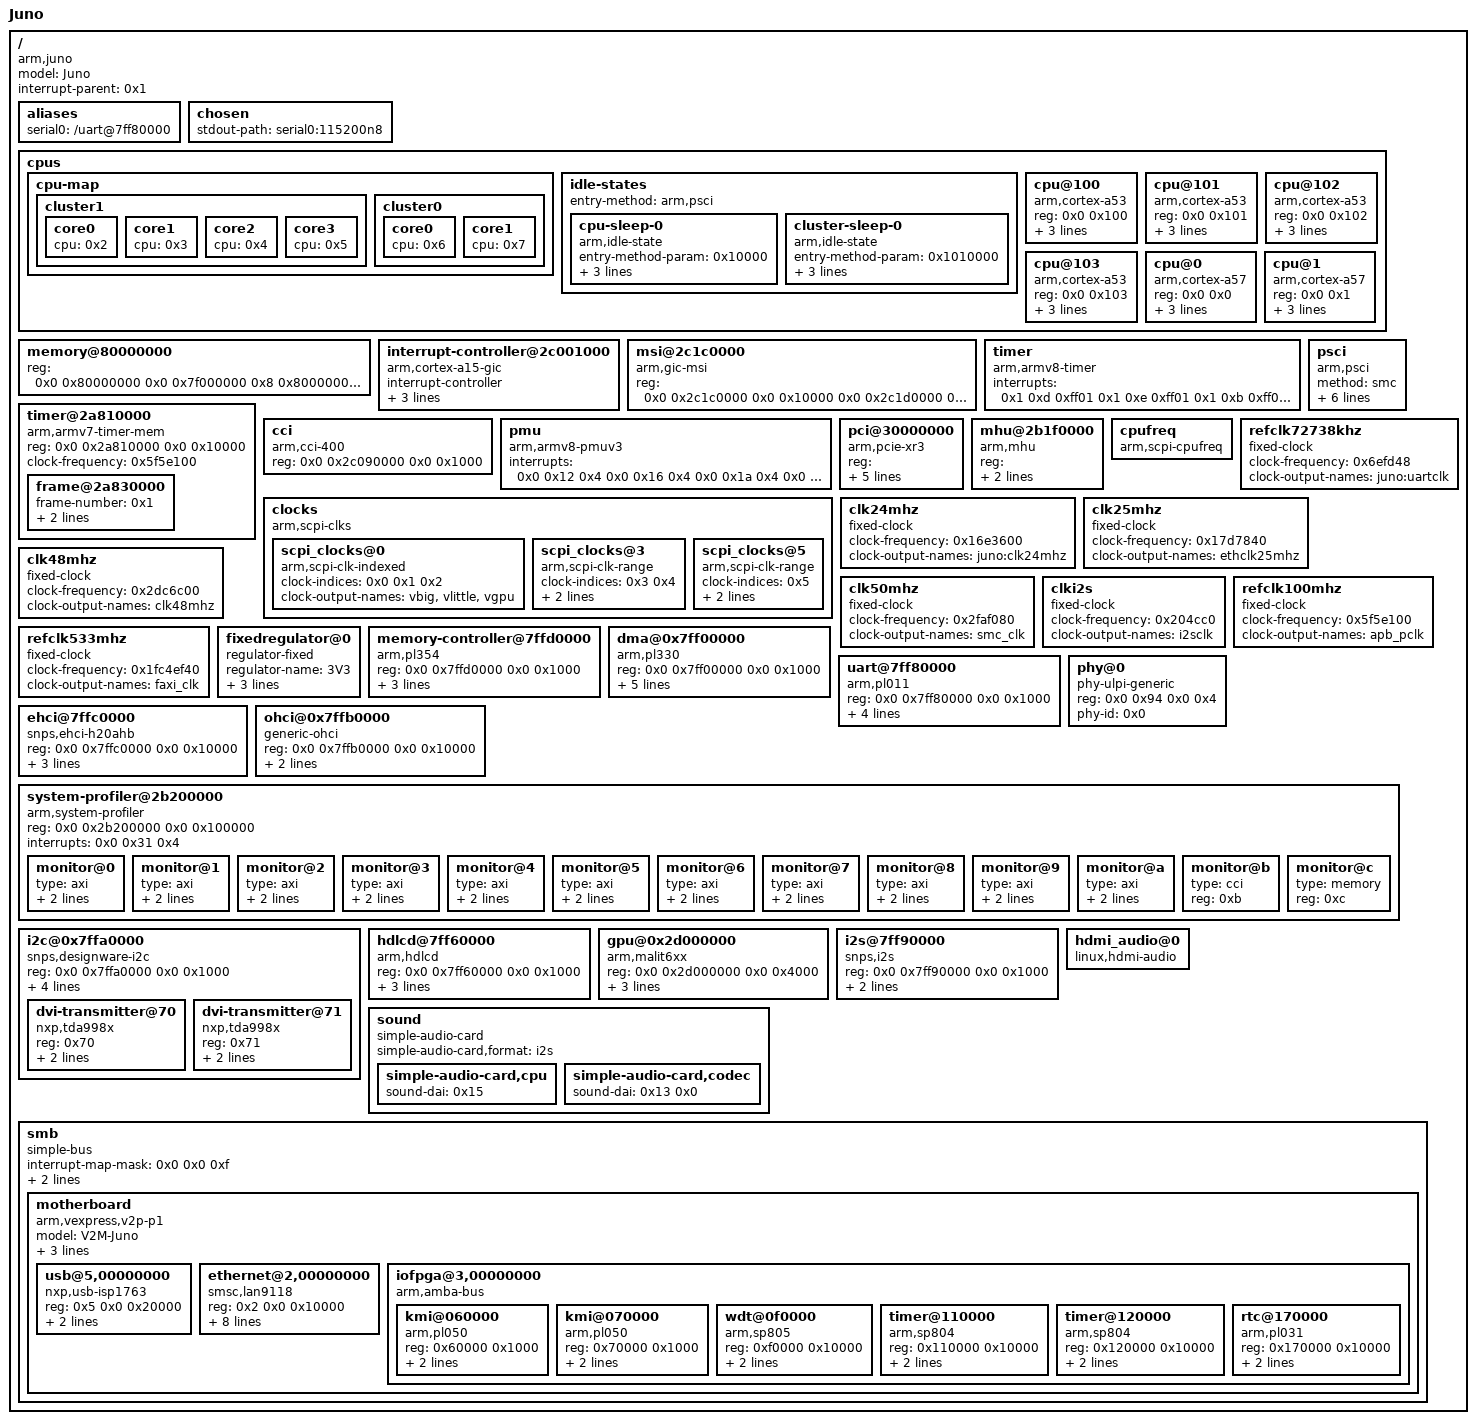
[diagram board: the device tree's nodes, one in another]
/dts-v1/;

/ {
	model = "Juno";
	compatible = "arm,juno", "arm,vexpress";
	interrupt-parent = <0x1>;
	#address-cells = <0x2>;
	#size-cells = <0x2>;

	aliases {
		serial0 = "/uart@7ff80000";
	};

	chosen {
		stdout-path = "serial0:115200n8";
	};

	cpus {
		#address-cells = <0x2>;
		#size-cells = <0x0>;

		cpu-map {

			cluster1 {

				core0 {
					cpu = <0x2>;
				};

				core1 {
					cpu = <0x3>;
				};

				core2 {
					cpu = <0x4>;
				};

				core3 {
					cpu = <0x5>;
				};
			};

			cluster0 {

				core0 {
					cpu = <0x6>;
				};

				core1 {
					cpu = <0x7>;
				};
			};
		};

		idle-states {
			entry-method = "arm,psci";

			cpu-sleep-0 {
				compatible = "arm,idle-state";
				entry-method-param = <0x10000>;
				entry-latency-us = <0x28>;
				exit-latency-us = <0x64>;
				min-residency-us = <0x96>;
				linux,phandle = <0x9>;
				phandle = <0x9>;
			};

			cluster-sleep-0 {
				compatible = "arm,idle-state";
				entry-method-param = <0x1010000>;
				entry-latency-us = <0x1f4>;
				exit-latency-us = <0x3e8>;
				min-residency-us = <0x9c4>;
				linux,phandle = <0xa>;
				phandle = <0xa>;
			};
		};

		cpu@100 {
			device_type = "cpu";
			compatible = "arm,cortex-a53", "arm,armv8";
			reg = <0x0 0x100>;
			enable-method = "psci";
			clocks = <0x8 0x1>;
			clock-names = "vlittle";
			cpu-idle-states = <0x9 0xa>;
			linux,phandle = <0x2>;
			phandle = <0x2>;
		};

		cpu@101 {
			device_type = "cpu";
			compatible = "arm,cortex-a53", "arm,armv8";
			reg = <0x0 0x101>;
			enable-method = "psci";
			clocks = <0x8 0x1>;
			clock-names = "vlittle";
			cpu-idle-states = <0x9 0xa>;
			linux,phandle = <0x3>;
			phandle = <0x3>;
		};

		cpu@102 {
			device_type = "cpu";
			compatible = "arm,cortex-a53", "arm,armv8";
			reg = <0x0 0x102>;
			enable-method = "psci";
			clocks = <0x8 0x1>;
			clock-names = "vlittle";
			cpu-idle-states = <0x9 0xa>;
			linux,phandle = <0x4>;
			phandle = <0x4>;
		};

		cpu@103 {
			device_type = "cpu";
			compatible = "arm,cortex-a53", "arm,armv8";
			reg = <0x0 0x103>;
			enable-method = "psci";
			clocks = <0x8 0x1>;
			clock-names = "vlittle";
			cpu-idle-states = <0x9 0xa>;
			linux,phandle = <0x5>;
			phandle = <0x5>;
		};

		cpu@0 {
			device_type = "cpu";
			compatible = "arm,cortex-a57", "arm,armv8";
			reg = <0x0 0x0>;
			enable-method = "psci";
			clocks = <0x8 0x0>;
			clock-names = "vbig";
			cpu-idle-states = <0x9 0xa>;
			linux,phandle = <0x6>;
			phandle = <0x6>;
		};

		cpu@1 {
			device_type = "cpu";
			compatible = "arm,cortex-a57", "arm,armv8";
			reg = <0x0 0x1>;
			enable-method = "psci";
			clocks = <0x8 0x0>;
			clock-names = "vbig";
			cpu-idle-states = <0x9 0xa>;
			linux,phandle = <0x7>;
			phandle = <0x7>;
		};
	};

	memory@80000000 {
		device_type = "memory";
		reg = <0x0 0x80000000 0x0 0x7f000000 0x8 0x80000000 0x1 0x80000000>;
	};

	interrupt-controller@2c001000 {
		compatible = "arm,cortex-a15-gic", "arm,cortex-a9-gic";
		#interrupt-cells = <0x3>;
		#address-cells = <0x0>;
		interrupt-controller;
		reg = <0x0 0x2c010000 0x0 0x1000 0x0 0x2c02f000 0x0 0x2000 0x0 0x2c04f000 0x0 0x2000 0x0 0x2c06f000 0x0 0x2000>;
		interrupts = <0x1 0x9 0xf04>;
		linux,phandle = <0x1>;
		phandle = <0x1>;
	};

	msi@2c1c0000 {
		compatible = "arm,gic-msi";
		reg = <0x0 0x2c1c0000 0x0 0x10000 0x0 0x2c1d0000 0x0 0x10000 0x0 0x2c1e0000 0x0 0x10000 0x0 0x2c1f0000 0x0 0x10000>;
	};

	timer {
		compatible = "arm,armv8-timer";
		interrupts = <0x1 0xd 0xff01 0x1 0xe 0xff01 0x1 0xb 0xff01 0x1 0xa 0xff01>;
	};

	timer@2a810000 {
		compatible = "arm,armv7-timer-mem";
		reg = <0x0 0x2a810000 0x0 0x10000>;
		clock-frequency = <0x5f5e100>;
		#address-cells = <0x2>;
		#size-cells = <0x2>;
		ranges;

		frame@2a830000 {
			frame-number = <0x1>;
			interrupts = <0x0 0x3c 0x4>;
			reg = <0x0 0x2a830000 0x0 0x10000>;
		};
	};

	cci {
		compatible = "arm,cci-400";
		reg = <0x0 0x2c090000 0x0 0x1000>;
	};

	pmu {
		compatible = "arm,armv8-pmuv3";
		interrupts = <0x0 0x12 0x4 0x0 0x16 0x4 0x0 0x1a 0x4 0x0 0x1e 0x4 0x0 0x2 0x4 0x0 0x6 0x4>;
	};

	psci {
		compatible = "arm,psci";
		method = "smc";
		cpu_suspend = <0xc4000001>;
		cpu_off = <0x84000002>;
		cpu_on = <0xc4000003>;
		migrate = <0xc4000005>;
		sys_poweroff = <0x84000008>;
		sys_reset = <0x84000009>;
	};

	pci@30000000 {
		compatible = "arm,pcie-xr3";
		device_type = "pci";
		reg = <0x0 0x7ff30000 0x0 0x1000 0x0 0x7ff20000 0x0 0x10000 0x0 0x40000000 0x0 0x10000000>;
		bus-range = <0x0 0xff>;
		#address-cells = <0x3>;
		#size-cells = <0x2>;
		ranges = <0x1000000 0x0 0x0 0x0 0x5ff00000 0x0 0x100000 0x2000000 0x0 0x0 0x0 0x40000000 0x0 0x1f000000>;
		#interrupt-cells = <0x1>;
		interrupt-map-mask = <0x0 0x0 0x0 0x7>;
		interrupt-map = <0x0 0x0 0x0 0x1 0x1 0x0 0x88 0x4 0x0 0x0 0x0 0x2 0x1 0x0 0x89 0x4 0x0 0x0 0x0 0x3 0x1 0x0 0x8a 0x4 0x0 0x0 0x0 0x4 0x1 0x0 0x8b 0x4>;
	};

	mhu@2b1f0000 {
		compatible = "arm,mhu";
		reg = <0x0 0x2b1f0000 0x0 0x10000 0x0 0x2e000000 0x0 0x10000>;
		interrupts = <0x0 0x24 0x4 0x0 0x23 0x4>;
	};

	clocks {
		compatible = "arm,scpi-clks";

		scpi_clocks@0 {
			compatible = "arm,scpi-clk-indexed";
			#clock-cells = <0x1>;
			clock-indices = <0x0 0x1 0x2>;
			clock-output-names = "vbig", "vlittle", "vgpu";
			linux,phandle = <0x8>;
			phandle = <0x8>;
		};

		scpi_clocks@3 {
			compatible = "arm,scpi-clk-range";
			#clock-cells = <0x1>;
			clock-indices = <0x3 0x4>;
			frequency-range = <0x16a6570 0x9d5b340>;
			clock-output-names = "pxlclk0", "pxlclk1";
			linux,phandle = <0x12>;
			phandle = <0x12>;
		};

		scpi_clocks@5 {
			compatible = "arm,scpi-clk-range";
			#clock-cells = <0x1>;
			clock-indices = <0x5>;
			frequency-range = <0x177000 0x8ca000>;
			clock-output-names = "i2s_clock";
			linux,phandle = <0x14>;
			phandle = <0x14>;
		};
	};

	cpufreq {
		compatible = "arm,scpi-cpufreq";
	};

	refclk72738khz {
		compatible = "fixed-clock";
		#clock-cells = <0x0>;
		clock-frequency = <0x6efd48>;
		clock-output-names = "juno:uartclk";
		linux,phandle = <0xd>;
		phandle = <0xd>;
	};

	clk24mhz {
		compatible = "fixed-clock";
		#clock-cells = <0x0>;
		clock-frequency = <0x16e3600>;
		clock-output-names = "juno:clk24mhz";
		linux,phandle = <0x18>;
		phandle = <0x18>;
	};

	clk25mhz {
		compatible = "fixed-clock";
		#clock-cells = <0x0>;
		clock-frequency = <0x17d7840>;
		clock-output-names = "ethclk25mhz";
		linux,phandle = <0x16>;
		phandle = <0x16>;
	};

	clk48mhz {
		compatible = "fixed-clock";
		#clock-cells = <0x0>;
		clock-frequency = <0x2dc6c00>;
		clock-output-names = "clk48mhz";
		linux,phandle = <0x10>;
		phandle = <0x10>;
	};

	clk50mhz {
		compatible = "fixed-clock";
		#clock-cells = <0x0>;
		clock-frequency = <0x2faf080>;
		clock-output-names = "smc_clk";
		linux,phandle = <0xb>;
		phandle = <0xb>;
	};

	clki2s {
		compatible = "fixed-clock";
		#clock-cells = <0x0>;
		clock-frequency = <0x204cc0>;
		clock-output-names = "i2sclk";
	};

	refclk100mhz {
		compatible = "fixed-clock";
		#clock-cells = <0x0>;
		clock-frequency = <0x5f5e100>;
		clock-output-names = "apb_pclk";
		linux,phandle = <0xe>;
		phandle = <0xe>;
	};

	refclk533mhz {
		compatible = "fixed-clock";
		#clock-cells = <0x0>;
		clock-frequency = <0x1fc4ef40>;
		clock-output-names = "faxi_clk";
		linux,phandle = <0xc>;
		phandle = <0xc>;
	};

	fixedregulator@0 {
		compatible = "regulator-fixed";
		regulator-name = "3V3";
		regulator-min-microvolt = <0x325aa0>;
		regulator-max-microvolt = <0x325aa0>;
		regulator-always-on;
		linux,phandle = <0x17>;
		phandle = <0x17>;
	};

	memory-controller@7ffd0000 {
		compatible = "arm,pl354", "arm,primecell";
		reg = <0x0 0x7ffd0000 0x0 0x1000>;
		interrupts = <0x0 0x56 0x4 0x0 0x57 0x4>;
		clocks = <0xb>;
		clock-names = "apb_pclk";
		chip5-memwidth = <0x10>;
	};

	dma@0x7ff00000 {
		compatible = "arm,pl330", "arm,primecell";
		reg = <0x0 0x7ff00000 0x0 0x1000>;
		interrupts = <0x0 0x5f 0x4 0x0 0x58 0x4 0x0 0x59 0x4 0x0 0x5a 0x4 0x0 0x5b 0x4 0x0 0x6c 0x4 0x0 0x6d 0x4 0x0 0x6e 0x4 0x0 0x6f 0x4>;
		#dma-cells = <0x1>;
		#dma-channels = <0x8>;
		#dma-requests = <0x20>;
		clocks = <0xc>;
		clock-names = "apb_pclk";
		linux,phandle = <0xf>;
		phandle = <0xf>;
	};

	uart@7ff80000 {
		compatible = "arm,pl011", "arm,primecell";
		reg = <0x0 0x7ff80000 0x0 0x1000>;
		interrupts = <0x0 0x53 0x4>;
		clocks = <0xd 0xe>;
		clock-names = "uartclk", "apb_pclk";
		dmas = <0xf 0x1 0xf 0x2>;
		dma-names = "rx", "tx";
		auto-poll = <0x1>;
	};

	phy@0 {
		compatible = "phy-ulpi-generic";
		reg = <0x0 0x94 0x0 0x4>;
		phy-id = <0x0>;
		linux,phandle = <0x11>;
		phandle = <0x11>;
	};

	ehci@7ffc0000 {
		compatible = "snps,ehci-h20ahb";
		reg = <0x0 0x7ffc0000 0x0 0x10000>;
		interrupts = <0x0 0x75 0x4>;
		clocks = <0x10>;
		clock-names = "otg";
		phys = <0x11>;
	};

	ohci@0x7ffb0000 {
		compatible = "generic-ohci";
		reg = <0x0 0x7ffb0000 0x0 0x10000>;
		interrupts = <0x0 0x74 0x4>;
		clocks = <0x10>;
		clock-names = "otg";
	};

	system-profiler@2b200000 {
		compatible = "arm,system-profiler";
		reg = <0x0 0x2b200000 0x0 0x100000>;
		#address-cells = <0x1>;
		#size-cells = <0x0>;
		interrupts = <0x0 0x31 0x4>;

		monitor@0 {
			type = "axi";
			reg = <0x0>;
			target = "cpu-cluster:cortex-a57";
		};

		monitor@1 {
			type = "axi";
			reg = <0x1>;
			target = "cpu-cluster:cortex-a53";
		};

		monitor@2 {
			type = "axi";
			reg = <0x2>;
			target = "gpu:mali-t6xx";
		};

		monitor@3 {
			type = "axi";
			reg = <0x3>;
			target = "link:cci-slave-s1";
		};

		monitor@4 {
			type = "axi";
			reg = <0x4>;
			target = "link:cci-to-pcie";
		};

		monitor@5 {
			type = "axi";
			reg = <0x5>;
			target = "link:pcie-to-cci";
		};

		monitor@6 {
			type = "axi";
			reg = <0x6>;
			target = "system-peripheral";
		};

		monitor@7 {
			type = "axi";
			reg = <0x7>;
			target = "dram:s1";
		};

		monitor@8 {
			type = "axi";
			reg = <0x8>;
			target = "dram:s2";
		};

		monitor@9 {
			type = "axi";
			reg = <0x9>;
			target = "dram:s3";
		};

		monitor@a {
			type = "axi";
			reg = <0xa>;
			target = "dram:s4";
		};

		monitor@b {
			type = "cci";
			reg = <0xb>;
		};

		monitor@c {
			type = "memory";
			reg = <0xc>;
		};
	};

	i2c@0x7ffa0000 {
		#address-cells = <0x1>;
		#size-cells = <0x0>;
		compatible = "snps,designware-i2c";
		reg = <0x0 0x7ffa0000 0x0 0x1000>;
		interrupts = <0x0 0x68 0x4>;
		clock-frequency = <0x186a0>;
		i2c-sda-hold-time-ns = <0x1f4>;
		clocks = <0xb>;

		dvi-transmitter@70 {
			compatible = "nxp,tda998x";
			reg = <0x70>;
			audio-ports = <0x3 0x4>;
			audio-port-names = "i2s", "spdif";
			#sound-dai-cells = <0x1>;
			linux,phandle = <0x13>;
			phandle = <0x13>;
		};

		dvi-transmitter@71 {
			compatible = "nxp,tda998x";
			reg = <0x71>;
			audio-ports = <0x3 0x4>;
			audio-port-names = "i2s", "spdif";
			#sound-dai-cells = <0x1>;
		};
	};

	hdlcd@7ff60000 {
		compatible = "arm,hdlcd";
		reg = <0x0 0x7ff60000 0x0 0x1000>;
		interrupts = <0x0 0x55 0x4>;
		clocks = <0x12 0x0>;
		clock-names = "pxlclk";
		i2c-slave = <0x13>;
	};

	gpu@0x2d000000 {
		compatible = "arm,malit6xx", "arm,mali";
		reg = <0x0 0x2d000000 0x0 0x4000>;
		interrupts = <0x0 0x21 0x4 0x0 0x22 0x4 0x0 0x20 0x4>;
		interrupt-names = "JOB", "MMU", "GPU";
		clocks = <0x8 0x2>;
		clock-names = "clk_mali";
	};

	i2s@7ff90000 {
		compatible = "snps,i2s";
		reg = <0x0 0x7ff90000 0x0 0x1000>;
		clocks = <0x14 0x0 0xe>;
		clock-names = "i2sclk", "apb_pclk";
		#sound-dai-cells = <0x0>;
		dmas = <0xf 0x5>;
		dma-names = "tx";
		linux,phandle = <0x15>;
		phandle = <0x15>;
	};

	hdmi_audio@0 {
		compatible = "linux,hdmi-audio";
		#sound-dai-cells = <0x0>;
		status = "okay";
	};

	sound {
		compatible = "simple-audio-card";
		simple-audio-card,format = "i2s";

		simple-audio-card,cpu {
			sound-dai = <0x15>;
		};

		simple-audio-card,codec {
			sound-dai = <0x13 0x0>;
		};
	};

	smb {
		compatible = "simple-bus";
		#address-cells = <0x2>;
		#size-cells = <0x1>;
		ranges = <0x0 0x0 0x0 0x8000000 0x4000000 0x1 0x0 0x0 0x14000000 0x4000000 0x2 0x0 0x0 0x18000000 0x4000000 0x3 0x0 0x0 0x1c000000 0x4000000 0x4 0x0 0x0 0xc000000 0x4000000 0x5 0x0 0x0 0x10000000 0x4000000>;
		#interrupt-cells = <0x1>;
		interrupt-map-mask = <0x0 0x0 0xf>;
		interrupt-map = <0x0 0x0 0x0 0x1 0x0 0x44 0x4 0x0 0x0 0x1 0x1 0x0 0x45 0x4 0x0 0x0 0x2 0x1 0x0 0x46 0x4 0x0 0x0 0x3 0x1 0x0 0xa0 0x4 0x0 0x0 0x4 0x1 0x0 0xa1 0x4 0x0 0x0 0x5 0x1 0x0 0xa2 0x4 0x0 0x0 0x6 0x1 0x0 0xa3 0x4 0x0 0x0 0x7 0x1 0x0 0xa4 0x4 0x0 0x0 0x8 0x1 0x0 0xa5 0x4 0x0 0x0 0x9 0x1 0x0 0xa6 0x4 0x0 0x0 0xa 0x1 0x0 0xa7 0x4 0x0 0x0 0xb 0x1 0x0 0xa8 0x4 0x0 0x0 0xc 0x1 0x0 0xa9 0x4>;

		motherboard {
			model = "V2M-Juno";
			arm,hbi = <0x252>;
			arm,vexpress,site = <0x0>;
			arm,v2m-memory-map = "rs1";
			compatible = "arm,vexpress,v2p-p1", "simple-bus";
			#address-cells = <0x2>;
			#size-cells = <0x1>;
			#interrupt-cells = <0x1>;
			ranges;

			usb@5,00000000 {
				compatible = "nxp,usb-isp1763";
				reg = <0x5 0x0 0x20000>;
				bus-width = <0x10>;
				interrupts = <0x4>;
			};

			ethernet@2,00000000 {
				compatible = "smsc,lan9118", "smsc,lan9115";
				reg = <0x2 0x0 0x10000>;
				interrupts = <0x3>;
				phy-mode = "mii";
				reg-io-width = <0x4>;
				smsc,irq-active-high;
				smsc,irq-push-pull;
				clocks = <0x16>;
				vdd33a-supply = <0x17>;
				vddvario-supply = <0x17>;
			};

			iofpga@3,00000000 {
				compatible = "arm,amba-bus", "simple-bus";
				#address-cells = <0x1>;
				#size-cells = <0x1>;
				ranges = <0x0 0x3 0x0 0x200000>;

				kmi@060000 {
					compatible = "arm,pl050", "arm,primecell";
					reg = <0x60000 0x1000>;
					interrupts = <0x8>;
					clocks = <0x18 0xb>;
					clock-names = "KMIREFCLK", "apb_pclk";
				};

				kmi@070000 {
					compatible = "arm,pl050", "arm,primecell";
					reg = <0x70000 0x1000>;
					interrupts = <0x8>;
					clocks = <0x18 0xb>;
					clock-names = "KMIREFCLK", "apb_pclk";
				};

				wdt@0f0000 {
					compatible = "arm,sp805", "arm,primecell";
					reg = <0xf0000 0x10000>;
					interrupts = <0x7>;
					clocks = <0x18 0xb>;
					clock-names = "wdogclk", "apb_pclk";
				};

				timer@110000 {
					compatible = "arm,sp804", "arm,primecell";
					reg = <0x110000 0x10000>;
					interrupts = <0x9>;
					clocks = <0x18 0xb>;
					clock-names = "timclken1", "apb_pclk";
				};

				timer@120000 {
					compatible = "arm,sp804", "arm,primecell";
					reg = <0x120000 0x10000>;
					interrupts = <0x9>;
					clocks = <0x18 0xb>;
					clock-names = "timclken1", "apb_pclk";
				};

				rtc@170000 {
					compatible = "arm,pl031", "arm,primecell";
					reg = <0x170000 0x10000>;
					interrupts = <0x0>;
					clocks = <0xb>;
					clock-names = "apb_pclk";
				};
			};
		};
	};
};
